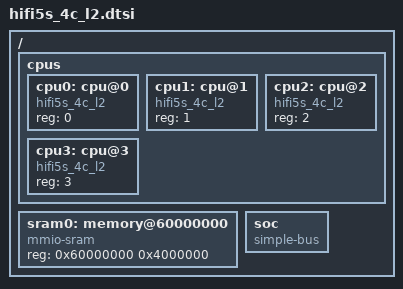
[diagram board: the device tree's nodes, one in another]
/*
 * Copyright (c) 2024 Cadence Design Systems, Inc.
 *
 * SPDX-License-Identifier: Apache-2.0
 */

#include "skeleton.dtsi"

/ {
	cpus {
		#address-cells = <1>;
		#size-cells = <0>;

		cpu0: cpu@0 {
			device_type = "cpu";
			compatible = "hifi5s_4c_l2";
			reg = <0>;
		};

		cpu1: cpu@1 {
			device_type = "cpu";
			compatible = "hifi5s_4c_l2";
			reg = <1>;
		};

		cpu2: cpu@2 {
			device_type = "cpu";
			compatible = "hifi5s_4c_l2";
			reg = <2>;
		};

		cpu3: cpu@3 {
			device_type = "cpu";
			compatible = "hifi5s_4c_l2";
			reg = <3>;
		};
	};

	sram0: memory@60000000 {
		device_type = "memory";
		compatible = "mmio-sram";
		reg = <0x60000000 0x4000000>;
	};

	soc {
		#address-cells = <1>;
		#size-cells = <1>;
		compatible = "simple-bus";
		ranges;

	};
};
